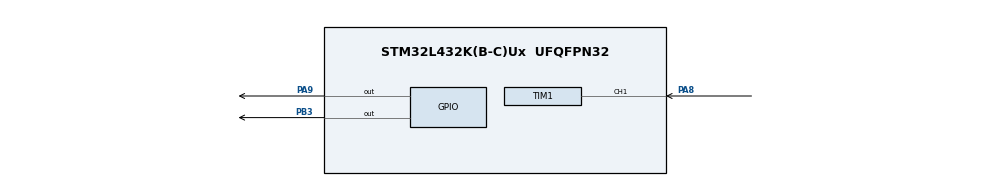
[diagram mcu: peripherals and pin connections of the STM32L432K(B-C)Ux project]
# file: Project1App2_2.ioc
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Mcu.Family=STM32L4
Mcu.Name=STM32L432K(B-C)Ux
Mcu.Package=UFQFPN32
NVIC.PriorityGroup=NVIC_PRIORITYGROUP_4
NVIC.TIM1_CC_IRQn=true\:0\:0\:false\:false\:true\:true
PA13\ (JTMS-SWDIO).Mode=Serial_Wire
PA13\ (JTMS-SWDIO).Signal=SYS_JTMS-SWDIO
PA14\ (JTCK-SWCLK).Mode=Serial_Wire
PA14\ (JTCK-SWCLK).Signal=SYS_JTCK-SWCLK
PA8.Signal=S_TIM1_CH1
PA9.Signal=GPIO_Output
PB3\ (JTDO-TRACESWO).Signal=GPIO_Output
PC14-OSC32_IN\ (PC14).Mode=LSE-External-Oscillator
PC14-OSC32_IN\ (PC14).Signal=RCC_OSC32_IN
PC15-OSC32_OUT\ (PC15).Mode=LSE-External-Oscillator
PC15-OSC32_OUT\ (PC15).Signal=RCC_OSC32_OUT
ProjectManager.HeapSize=0x200
ProjectManager.StackSize=0x400
ProjectManager.TargetToolchain=MDK-ARM V5
RCC.HSE_VALUE=8000000
RCC.HSI48_VALUE=48000000
RCC.HSI_VALUE=16000000
RCC.MSI_VALUE=4000000
RCC.VCOOutputFreq_Value=32000000
SH.S_TIM1_CH1.0=TIM1_CH1,Input_Capture1_from_TI1
TIM1.Channel-Input_Capture1_from_TI1=TIM_CHANNEL_1
TIM1.Period=0xffff-1
TIM1.Prescaler=8-1
VP_TIM1_VS_ClockSourceINT.Mode=Internal
board=custom

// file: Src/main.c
/* USER CODE BEGIN Header */
/**
  ******************************************************************************
  * @file           : main.c
  * @brief          : Main program body
  ******************************************************************************
  ** This notice applies to any and all portions of this file
  * that are not between comment pairs USER CODE BEGIN and
  * USER CODE END. Other portions of this file, whether
  * inserted by the user or by software development tools
  * are owned by their respective copyright owners.
  *
  * COPYRIGHT(c) 2021 STMicroelectronics
  *
  * Redistribution and use in source and binary forms, with or without modification,
  * are permitted provided that the following conditions are met:
  *   1. Redistributions of source code must retain the above copyright notice,
  *      this list of conditions and the following disclaimer.
  *   2. Redistributions in binary form must reproduce the above copyright notice,
  *      this list of conditions and the following disclaimer in the documentation
  *      and/or other materials provided with the distribution.
  *   3. Neither the name of STMicroelectronics nor the names of its contributors
  *      may be used to endorse or promote products derived from this software
  *      without specific prior written permission.
  *
  * THIS SOFTWARE IS PROVIDED BY THE COPYRIGHT HOLDERS AND CONTRIBUTORS "AS IS"
  * AND ANY EXPRESS OR IMPLIED WARRANTIES, INCLUDING, BUT NOT LIMITED TO, THE
  * IMPLIED WARRANTIES OF MERCHANTABILITY AND FITNESS FOR A PARTICULAR PURPOSE ARE
  * DISCLAIMED. IN NO EVENT SHALL THE COPYRIGHT HOLDER OR CONTRIBUTORS BE LIABLE
  * FOR ANY DIRECT, INDIRECT, INCIDENTAL, SPECIAL, EXEMPLARY, OR CONSEQUENTIAL
  * DAMAGES (INCLUDING, BUT NOT LIMITED TO, PROCUREMENT OF SUBSTITUTE GOODS OR
  * SERVICES; LOSS OF USE, DATA, OR PROFITS; OR BUSINESS INTERRUPTION) HOWEVER
  * CAUSED AND ON ANY THEORY OF LIABILITY, WHETHER IN CONTRACT, STRICT LIABILITY,
  * OR TORT (INCLUDING NEGLIGENCE OR OTHERWISE) ARISING IN ANY WAY OUT OF THE USE
  * OF THIS SOFTWARE, EVEN IF ADVISED OF THE POSSIBILITY OF SUCH DAMAGE.
  *
  ******************************************************************************
  */
/* USER CODE END Header */

#include  <stdio.h>
#include <stdlib.h>
#include <stdint.h>
#include <stdbool.h>
#include "main.h"
#include "stm32l4xx_it.h"
#include  "hcSR04.h"

TIM_HandleTypeDef htim1;

bool flag=true;
struct task tasktoberemoved;

typedef void (*fptr)();

struct taskQueue {
	int CURRENTSIZE;
	int MAXSIZE;
	struct task *tasks;
};

struct taskQueue ready_queue;
struct taskQueue delay_queue;

struct task {
    int priority;
    fptr pointer_to_func;
    int delay;
};

void  insertintodelay(fptr f, int delay, int prio){
    delay_queue.tasks[delay_queue.CURRENTSIZE].delay=delay+1;
    delay_queue.tasks[delay_queue.CURRENTSIZE].priority= prio;
    delay_queue.tasks[delay_queue.CURRENTSIZE].pointer_to_func =f;
    delay_queue.CURRENTSIZE++;

    for (int i=0; i<delay_queue.CURRENTSIZE;i++){
        for (int j=0; j<delay_queue.CURRENTSIZE;j++){
            if (delay_queue.tasks[i].delay < delay_queue.tasks[j].delay && i!=j){

                struct task temp = delay_queue.tasks[i];
	            delay_queue.tasks[i] = delay_queue.tasks[j];
	            delay_queue.tasks[j] = temp;
            }
        }
    }
}

void QueTask(fptr f, int Priority)
{
    ready_queue.tasks[ready_queue.CURRENTSIZE].priority=Priority;
    ready_queue.tasks[ready_queue.CURRENTSIZE].pointer_to_func =f;
    ready_queue.CURRENTSIZE++;

    for (int i=0; i<ready_queue.CURRENTSIZE;i++){
        for (int j=0; j<ready_queue.CURRENTSIZE;j++){
            if (ready_queue.tasks[i].priority > ready_queue.tasks[j].priority && i!=j){

                struct task temp = ready_queue.tasks[i];
	            ready_queue.tasks[i] = ready_queue.tasks[j];
	            ready_queue.tasks[j] = temp;
            }
        }
    }

}

void ReRunMe(int delay){
    if (delay==0) {
        QueTask(tasktoberemoved.pointer_to_func, tasktoberemoved.priority);
    }
    else {
        insertintodelay(tasktoberemoved.pointer_to_func, delay, tasktoberemoved.priority);
    }
}

void Nothing(){

			flag=false;

}

 void init()
{
		int size=10;
    ready_queue.CURRENTSIZE=0;
    ready_queue.MAXSIZE=size;
    ready_queue.tasks = (struct task*)malloc(size * sizeof(struct task));

    delay_queue.CURRENTSIZE=0;
    delay_queue.MAXSIZE=size;
    delay_queue.tasks = (struct task*)malloc(size * sizeof(struct task));

    for(int i=0;i< size; i++)
        {
            ready_queue.tasks[i].priority=-1;
            ready_queue.tasks[i].delay=99999;
            ready_queue.tasks[i].pointer_to_func = &Nothing;

            delay_queue.tasks[i].priority=-1;
            delay_queue.tasks[i].delay=99999;
            delay_queue.tasks[i].pointer_to_func = &Nothing;
        }
}

void dispatch(){

	if(flag==true)
	{
		if (ready_queue.CURRENTSIZE > 0){
					//printf("Enter dispatch and readqqueue!=0 ");

				tasktoberemoved = ready_queue.tasks[0];//fiha bassel fel awel
					for (int i=0;i<ready_queue.CURRENTSIZE;i++)
							ready_queue.tasks[i] = ready_queue.tasks[i+1];

					ready_queue.CURRENTSIZE--;
					ready_queue.tasks[ready_queue.CURRENTSIZE].priority = -1;
					ready_queue.tasks[ready_queue.CURRENTSIZE].delay=99999;
					ready_queue.tasks[ready_queue.CURRENTSIZE].pointer_to_func = &Nothing;

					tasktoberemoved.pointer_to_func();

			}
		 else if (ready_queue.CURRENTSIZE==0)//if no tasks in ready queue in this tick now
					{
							Nothing();
					}
					int i=0;
				while(delay_queue.CURRENTSIZE!=0)
							{
								if(delay_queue.tasks[i].delay== 99999)
											break;
								if(delay_queue.tasks[0].delay==0)
											{
													QueTask(delay_queue.tasks[0].pointer_to_func,delay_queue.tasks[0].priority);

													for (int i=0;i<delay_queue.CURRENTSIZE;i++)
															delay_queue.tasks[i] = delay_queue.tasks[i+1];
													delay_queue.CURRENTSIZE--;
													delay_queue.tasks[delay_queue.CURRENTSIZE].priority = -1;
													delay_queue.tasks[delay_queue.CURRENTSIZE].delay=99999;
													delay_queue.tasks[delay_queue.CURRENTSIZE].pointer_to_func = &Nothing;
													i--;
											}
									i++;
							}
	}
}

/* USER CODE END PV */

void SystemClock_Config(void);
static void MX_GPIO_Init(void);
static void MX_TIM1_Init(void);

int main(void)
{

  /* MCU Configuration--------------------------------------------------------*/

  /* Reset of all peripherals, Initializes the Flash interface and the Systick. */
  HAL_Init();

  /* Configure the system clock */
  SystemClock_Config();

  /* Initialize all configured peripherals */
  MX_GPIO_Init();
  MX_TIM1_Init();
  /* USER CODE BEGIN 2 */

	init();
  QueTask(&ReadDistance,5);//Highest Priority (5)
  QueTask(&ToggleAlarm,3);
  QueTask(&WaitForEachTick,1);//Lowest Priority (1)
  HAL_TIM_IC_Start_IT(&htim1,TIM_CHANNEL_1);
  /* USER CODE END 2 */

  /* Infinite loop */
	while (1)
  {
		dispatch();
  }
  /* USER CODE END 3 */
}

void SystemClock_Config(void)
{
  RCC_OscInitTypeDef RCC_OscInitStruct = {0};
  RCC_ClkInitTypeDef RCC_ClkInitStruct = {0};

  /**Configure LSE Drive Capability
  */
  HAL_PWR_EnableBkUpAccess();
  __HAL_RCC_LSEDRIVE_CONFIG(RCC_LSEDRIVE_LOW);
  /**Initializes the CPU, AHB and APB busses clocks
  */
  RCC_OscInitStruct.OscillatorType = RCC_OSCILLATORTYPE_LSE|RCC_OSCILLATORTYPE_MSI;
  RCC_OscInitStruct.LSEState = RCC_LSE_ON;
  RCC_OscInitStruct.MSIState = RCC_MSI_ON;
  RCC_OscInitStruct.MSICalibrationValue = 0;
  RCC_OscInitStruct.MSIClockRange = RCC_MSIRANGE_6;
  RCC_OscInitStruct.PLL.PLLState = RCC_PLL_NONE;
  if (HAL_RCC_OscConfig(&RCC_OscInitStruct) != HAL_OK)
  {
    Error_Handler();
  }
  /**Initializes the CPU, AHB and APB busses clocks
  */
  RCC_ClkInitStruct.ClockType = RCC_CLOCKTYPE_HCLK|RCC_CLOCKTYPE_SYSCLK
                              |RCC_CLOCKTYPE_PCLK1|RCC_CLOCKTYPE_PCLK2;
  RCC_ClkInitStruct.SYSCLKSource = RCC_SYSCLKSOURCE_MSI;
  RCC_ClkInitStruct.AHBCLKDivider = RCC_SYSCLK_DIV1;
  RCC_ClkInitStruct.APB1CLKDivider = RCC_HCLK_DIV1;
  RCC_ClkInitStruct.APB2CLKDivider = RCC_HCLK_DIV1;

  if (HAL_RCC_ClockConfig(&RCC_ClkInitStruct, FLASH_LATENCY_0) != HAL_OK)
  {
    Error_Handler();
  }
  /**Configure the main internal regulator output voltage
  */
  if (HAL_PWREx_ControlVoltageScaling(PWR_REGULATOR_VOLTAGE_SCALE1) != HAL_OK)
  {
    Error_Handler();
  }
  /**Enable MSI Auto calibration
  */
		HAL_SYSTICK_Config(HAL_RCC_GetHCLKFreq()*0.05); //0.05 represets 1 tick (50ms)
	/**Configure the Systick
    */
  HAL_SYSTICK_CLKSourceConfig(SYSTICK_CLKSOURCE_HCLK);
  /* SysTick_IRQn interrupt configuration */
  HAL_NVIC_SetPriority(SysTick_IRQn, 0, 0);
  HAL_RCCEx_EnableMSIPLLMode();
}

static void MX_TIM1_Init(void)
{

  TIM_ClockConfigTypeDef sClockSourceConfig = {0};
  TIM_MasterConfigTypeDef sMasterConfig = {0};
  TIM_IC_InitTypeDef sConfigIC = {0};

  htim1.Instance = TIM1;
  htim1.Init.Prescaler = 8-1;
  htim1.Init.CounterMode = TIM_COUNTERMODE_UP;
  htim1.Init.Period = 0xffff-1;
  htim1.Init.ClockDivision = TIM_CLOCKDIVISION_DIV1;
  htim1.Init.RepetitionCounter = 0;
  htim1.Init.AutoReloadPreload = TIM_AUTORELOAD_PRELOAD_DISABLE;
  if (HAL_TIM_Base_Init(&htim1) != HAL_OK)
  {
    Error_Handler();
  }
  sClockSourceConfig.ClockSource = TIM_CLOCKSOURCE_INTERNAL;
  if (HAL_TIM_ConfigClockSource(&htim1, &sClockSourceConfig) != HAL_OK)
  {
    Error_Handler();
  }
  if (HAL_TIM_IC_Init(&htim1) != HAL_OK)
  {
    Error_Handler();
  }
  sMasterConfig.MasterOutputTrigger = TIM_TRGO_RESET;
  sMasterConfig.MasterOutputTrigger2 = TIM_TRGO2_RESET;
  sMasterConfig.MasterSlaveMode = TIM_MASTERSLAVEMODE_DISABLE;
  if (HAL_TIMEx_MasterConfigSynchronization(&htim1, &sMasterConfig) != HAL_OK)
  {
    Error_Handler();
  }
  sConfigIC.ICPolarity = TIM_INPUTCHANNELPOLARITY_RISING;
  sConfigIC.ICSelection = TIM_ICSELECTION_DIRECTTI;
  sConfigIC.ICPrescaler = TIM_ICPSC_DIV1;
  sConfigIC.ICFilter = 0;
  if (HAL_TIM_IC_ConfigChannel(&htim1, &sConfigIC, TIM_CHANNEL_1) != HAL_OK)
  {
    Error_Handler();
  }

}

static void MX_GPIO_Init(void)
{
  GPIO_InitTypeDef GPIO_InitStruct = {0};

  /* GPIO Ports Clock Enable */
  __HAL_RCC_GPIOC_CLK_ENABLE();
  __HAL_RCC_GPIOA_CLK_ENABLE();
  __HAL_RCC_GPIOB_CLK_ENABLE();

  /*Configure GPIO pin Output Level */
  HAL_GPIO_WritePin(GPIOA, GPIO_PIN_9, GPIO_PIN_RESET);

  /*Configure GPIO pin Output Level */
  HAL_GPIO_WritePin(GPIOB, GPIO_PIN_3, GPIO_PIN_RESET);

  /*Configure GPIO pin : PA9 */
  GPIO_InitStruct.Pin = GPIO_PIN_9;
  GPIO_InitStruct.Mode = GPIO_MODE_OUTPUT_PP;
  GPIO_InitStruct.Pull = GPIO_NOPULL;
  GPIO_InitStruct.Speed = GPIO_SPEED_FREQ_LOW;
  HAL_GPIO_Init(GPIOA, &GPIO_InitStruct);

  /*Configure GPIO pin : PB3 */
  GPIO_InitStruct.Pin = GPIO_PIN_3;
  GPIO_InitStruct.Mode = GPIO_MODE_OUTPUT_PP;
  GPIO_InitStruct.Pull = GPIO_NOPULL;
  GPIO_InitStruct.Speed = GPIO_SPEED_FREQ_LOW;
  HAL_GPIO_Init(GPIOB, &GPIO_InitStruct);

}

void Error_Handler(void)
{
}

/************************ (C) COPYRIGHT STMicroelectronics *****END OF FILE****/
